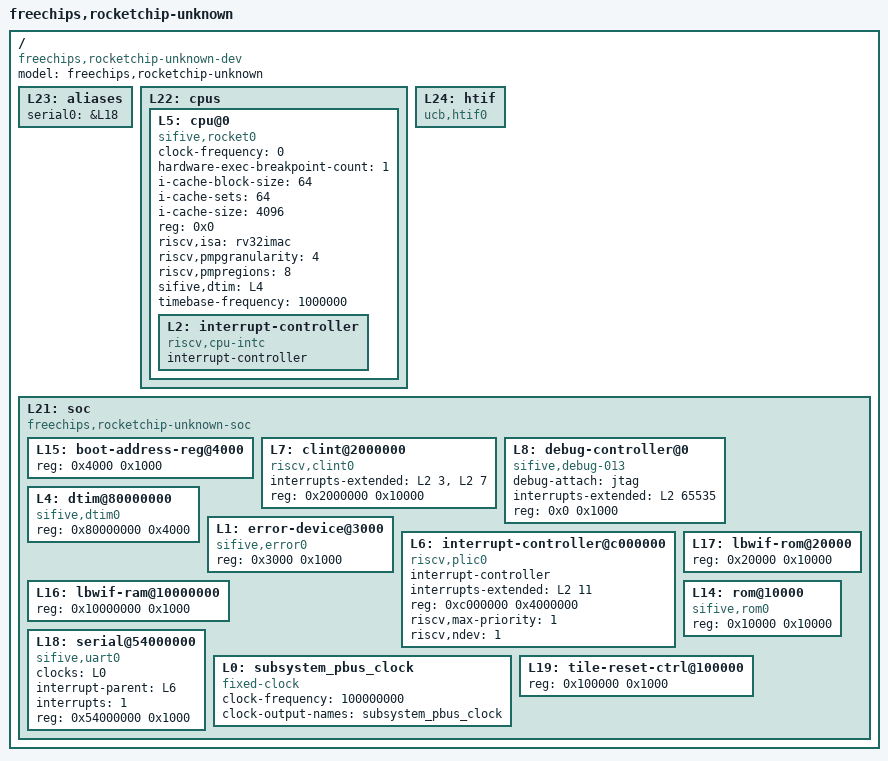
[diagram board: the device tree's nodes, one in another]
/dts-v1/;

/ {
	#address-cells = <1>;
	#size-cells = <1>;
	compatible = "freechips,rocketchip-unknown-dev";
	model = "freechips,rocketchip-unknown";
	L23: aliases {
		serial0 = &L18;
	};
	L22: cpus {
		#address-cells = <1>;
		#size-cells = <0>;
		L5: cpu@0 {
			clock-frequency = <0>;
			compatible = "sifive,rocket0", "riscv";
			device_type = "cpu";
			hardware-exec-breakpoint-count = <1>;
			i-cache-block-size = <64>;
			i-cache-sets = <64>;
			i-cache-size = <4096>;
			reg = <0x0>;
			riscv,isa = "rv32imac";
			riscv,pmpgranularity = <4>;
			riscv,pmpregions = <8>;
			sifive,dtim = <&L4>;
			status = "okay";
			timebase-frequency = <1000000>;
			L2: interrupt-controller {
				#interrupt-cells = <1>;
				compatible = "riscv,cpu-intc";
				interrupt-controller;
			};
		};
	};
	L24: htif {
		compatible = "ucb,htif0";
	};
	L21: soc {
		#address-cells = <1>;
		#size-cells = <1>;
		compatible = "freechips,rocketchip-unknown-soc", "simple-bus";
		ranges;
		L15: boot-address-reg@4000 {
			reg = <0x4000 0x1000>;
			reg-names = "control";
		};
		L7: clint@2000000 {
			compatible = "riscv,clint0";
			interrupts-extended = <&L2 3 &L2 7>;
			reg = <0x2000000 0x10000>;
			reg-names = "control";
		};
		L8: debug-controller@0 {
			compatible = "sifive,debug-013", "riscv,debug-013";
			debug-attach = "jtag";
			interrupts-extended = <&L2 65535>;
			reg = <0x0 0x1000>;
			reg-names = "control";
		};
		L4: dtim@80000000 {
			compatible = "sifive,dtim0";
			reg = <0x80000000 0x4000>;
			reg-names = "mem";
		};
		L1: error-device@3000 {
			compatible = "sifive,error0";
			reg = <0x3000 0x1000>;
		};
		L6: interrupt-controller@c000000 {
			#interrupt-cells = <1>;
			compatible = "riscv,plic0";
			interrupt-controller;
			interrupts-extended = <&L2 11>;
			reg = <0xc000000 0x4000000>;
			reg-names = "control";
			riscv,max-priority = <1>;
			riscv,ndev = <1>;
		};
		L16: lbwif-ram@10000000 {
			reg = <0x10000000 0x1000>;
		};
		L17: lbwif-rom@20000 {
			reg = <0x20000 0x10000>;
		};
		L14: rom@10000 {
			compatible = "sifive,rom0";
			reg = <0x10000 0x10000>;
			reg-names = "mem";
		};
		L18: serial@54000000 {
			clocks = <&L0>;
			compatible = "sifive,uart0";
			interrupt-parent = <&L6>;
			interrupts = <1>;
			reg = <0x54000000 0x1000>;
			reg-names = "control";
		};
		L0: subsystem_pbus_clock {
			#clock-cells = <0>;
			clock-frequency = <100000000>;
			clock-output-names = "subsystem_pbus_clock";
			compatible = "fixed-clock";
		};
		L19: tile-reset-ctrl@100000 {
			reg = <0x100000 0x1000>;
			reg-names = "control";
		};
	};
};
